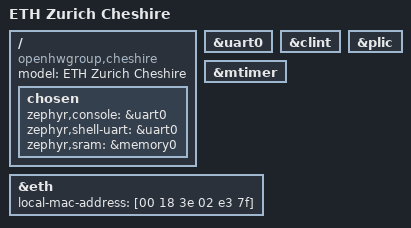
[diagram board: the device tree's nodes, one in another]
/*
 * Copyright 2024 ETH Zurich
 * SPDX-License-Identifier: Apache-2.0
 */
/dts-v1/;

#include <openhwgroup/cheshire.dtsi>

/ {
	model = "ETH Zurich Cheshire";
	compatible = "openhwgroup,cheshire";

	chosen {
		zephyr,console = &uart0;
		zephyr,shell-uart = &uart0;
		zephyr,sram = &memory0;
	};
};

&uart0 {
	status = "okay";
};

&clint {
	status = "okay";
};
&mtimer {
	status = "okay";
};

&plic {
	status = "okay";
};

&eth {
	local-mac-address = [00 18 3e 02 e3 7f];
	status = "okay";
};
